# nrf52833 register map
Vendor: Nordic Semiconductor; Series: nrf52; File version: 1
CPU: CM4 r0p1, little endian, MPU, FPU, 3 interrupt priority bits
Registers are 32-bit, read-write, reset 0x0 unless marked. A register's access mark holds for its fields unless they carry their own. Offsets are from the block's base; [hi:lo] are bit positions; 'fields as' and 'values as' point back to an identical list.

## TEMP — Temperature Sensor
Base 0x4000C000
0x00 TASKS_START wo — Start temperature measurement
  [0] TASKS_START
    1=Trigger task
0x04 TASKS_STOP wo — Stop temperature measurement
  [0] TASKS_STOP
    1=Trigger task
0x100 EVENTS_DATARDY — Temperature measurement complete, data ready
  [0] EVENTS_DATARDY
    0=NotGenerated (Event not generated); 1=Generated (Event generated)
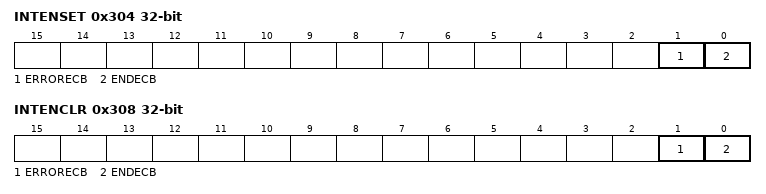
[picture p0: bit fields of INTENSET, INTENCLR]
0x304 INTENSET — Enable interrupt
  [0] DATARDY — Write '1' to enable interrupt for event DATARDY
    on read: 0=Disabled (Read: Disabled); 1=Enabled (Read: Enabled) | on write: 1=Set (Enable)
0x308 INTENCLR — Disable interrupt
  [0] DATARDY — Write '1' to disable interrupt for event DATARDY
    on read: 0=Disabled (Read: Disabled); 1=Enabled (Read: Enabled) | on write: 1=Clear (Disable)
0x508 TEMP ro — Temperature in degC (0.25deg steps)
0x520 A0 reset 0x326 — Slope of first piecewise linear function
  [11:0] A0
0x524 A1 reset 0x348 — Slope of second piecewise linear function
  [11:0] A1
0x528 A2 reset 0x3AA — Slope of third piecewise linear function
  [11:0] A2
0x52C A3 reset 0x40E — Slope of fourth piecewise linear function
  [11:0] A3
0x530 A4 reset 0x4BD — Slope of fifth piecewise linear function
  [11:0] A4
0x534 A5 reset 0x5A3 — Slope of sixth piecewise linear function
  [11:0] A5
0x540 B0 reset 0x3FEF — y-intercept of first piecewise linear function
  [13:0] B0
0x544 B1 reset 0x3FBE — y-intercept of second piecewise linear function
  [13:0] B1
0x548 B2 reset 0x3FBE — y-intercept of third piecewise linear function
  [13:0] B2
0x54C B3 reset 0x12 — y-intercept of fourth piecewise linear function
  [13:0] B3
0x550 B4 reset 0x124 — y-intercept of fifth piecewise linear function
  [13:0] B4
0x554 B5 reset 0x27C — y-intercept of sixth piecewise linear function
  [13:0] B5
0x560 T0 reset 0xE2 — End point of first piecewise linear function
  [7:0] T0
0x564 T1 — End point of second piecewise linear function
  [7:0] T1
0x568 T2 reset 0x19 — End point of third piecewise linear function
  [7:0] T2
0x56C T3 reset 0x3C — End point of fourth piecewise linear function
  [7:0] T3
0x570 T4 reset 0x50 — End point of fifth piecewise linear function
  [7:0] T4

## RNG — Random Number Generator
Base 0x4000D000
0x00 TASKS_START wo — Task starting the random number generator
  [0] TASKS_START
    1=Trigger task
0x04 TASKS_STOP wo — Task stopping the random number generator
  [0] TASKS_STOP
    1=Trigger task
0x100 EVENTS_VALRDY — Event being generated for every new random number written to the VALUE register
  [0] EVENTS_VALRDY
    0=NotGenerated (Event not generated); 1=Generated (Event generated)
0x200 SHORTS — Shortcuts between local events and tasks
  [0] VALRDY_STOP — Shortcut between event VALRDY and task STOP
    0=Disabled (Disable shortcut); 1=Enabled (Enable shortcut)
0x304 INTENSET — Enable interrupt
  [0] VALRDY — Write '1' to enable interrupt for event VALRDY
    on read: 0=Disabled (Read: Disabled); 1=Enabled (Read: Enabled) | on write: 1=Set (Enable)
0x308 INTENCLR — Disable interrupt
  [0] VALRDY — Write '1' to disable interrupt for event VALRDY
    on read: 0=Disabled (Read: Disabled); 1=Enabled (Read: Enabled) | on write: 1=Clear (Disable)
0x504 CONFIG — Configuration register
  [0] DERCEN — Bias correction
    0=Disabled; 1=Enabled
0x508 VALUE ro — Output random number
  [7:0] VALUE — Generated random number

## ECB — AES ECB Mode Encryption
Base 0x4000E000
0x00 TASKS_STARTECB wo — Start ECB block encrypt
  [0] TASKS_STARTECB
    1=Trigger task
0x04 TASKS_STOPECB wo — Abort a possible executing ECB operation
  [0] TASKS_STOPECB
    1=Trigger task
0x100 EVENTS_ENDECB — ECB block encrypt complete
  [0] EVENTS_ENDECB
    0=NotGenerated (Event not generated); 1=Generated (Event generated)
0x104 EVENTS_ERRORECB — ECB block encrypt aborted because of a STOPECB task or due to an error
  [0] EVENTS_ERRORECB
    values as EVENTS_ENDECB.EVENTS_ENDECB
0x304 INTENSET — Enable interrupt
  [1] ERRORECB — Write '1' to enable interrupt for event ERRORECB
    on read: 0=Disabled (Read: Disabled); 1=Enabled (Read: Enabled) | on write: 1=Set (Enable)
  [0] ENDECB — Write '1' to enable interrupt for event ENDECB
    values as ERRORECB
0x308 INTENCLR — Disable interrupt
  [1] ERRORECB — Write '1' to disable interrupt for event ERRORECB
    on read: 0=Disabled (Read: Disabled); 1=Enabled (Read: Enabled) | on write: 1=Clear (Disable)
  [0] ENDECB — Write '1' to disable interrupt for event ENDECB
    values as ERRORECB
0x504 ECBDATAPTR — ECB block encrypt memory pointers
  [31:0] ECBDATAPTR — Pointer to the ECB data structure (see Table 1 ECB data structure overview)
